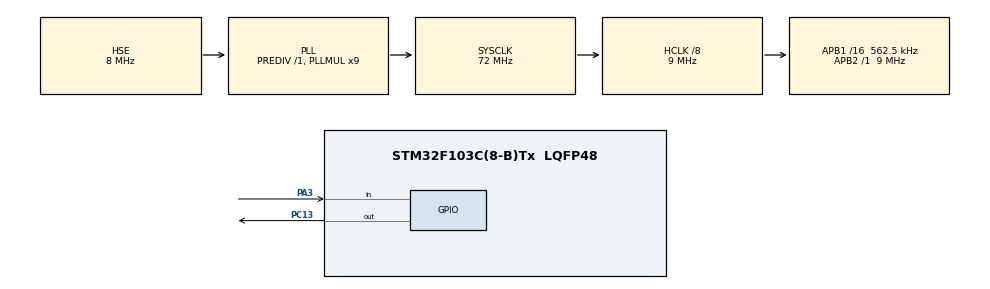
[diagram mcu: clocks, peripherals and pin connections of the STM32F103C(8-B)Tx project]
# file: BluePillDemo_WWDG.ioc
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Mcu.Family=STM32F1
Mcu.Name=STM32F103C(8-B)Tx
Mcu.Package=LQFP48
NVIC.PriorityGroup=NVIC_PRIORITYGROUP_4
PA13.Mode=Serial_Wire
PA13.Signal=SYS_JTMS-SWDIO
PA14.Mode=Serial_Wire
PA14.Signal=SYS_JTCK-SWCLK
PA3.GPIO_PuPd=GPIO_PULLUP
PA3.Signal=GPIO_Input
PC13-TAMPER-RTC.Signal=GPIO_Output
PC14-OSC32_IN.Mode=LSE-External-Oscillator
PC14-OSC32_IN.Signal=RCC_OSC32_IN
PC15-OSC32_OUT.Mode=LSE-External-Oscillator
PC15-OSC32_OUT.Signal=RCC_OSC32_OUT
PD0-OSC_IN.Mode=HSE-External-Oscillator
PD0-OSC_IN.Signal=RCC_OSC_IN
PD1-OSC_OUT.Mode=HSE-External-Oscillator
PD1-OSC_OUT.Signal=RCC_OSC_OUT
ProjectManager.HeapSize=0x200
ProjectManager.StackSize=0x400
ProjectManager.TargetToolchain=STM32CubeIDE
RCC.AHBCLKDivider=RCC_SYSCLK_DIV8
RCC.AHBFreq_Value=9000000
RCC.APB1CLKDivider=RCC_HCLK_DIV16
RCC.APB1Freq_Value=562500
RCC.APB1TimFreq_Value=1125000
RCC.APB2Freq_Value=9000000
RCC.APB2TimFreq_Value=9000000
RCC.HCLKFreq_Value=9000000
RCC.PLLMUL=RCC_PLL_MUL9
RCC.PLLSourceVirtual=RCC_PLLSOURCE_HSE
RCC.SYSCLKFreq_VALUE=72000000
RCC.SYSCLKSource=RCC_SYSCLKSOURCE_PLLCLK
RCC.USBFreq_Value=72000000
VP_WWDG_VS_WWDG.Mode=WWDG_Activate
WWDG.Counter=0x7f
WWDG.Prescaler=WWDG_PRESCALER_8
WWDG.Window=0x5f
board=custom

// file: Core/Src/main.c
/* USER CODE BEGIN Header */
/**
  ******************************************************************************
  * @file           : main.c
  * @brief          : Main program body
  ******************************************************************************
  * @attention
  *
  * <h2><center>&copy; Copyright (c) 2020 STMicroelectronics.
  * All rights reserved.</center></h2>
  *
  * This software component is licensed by ST under BSD 3-Clause license,
  * the "License"; You may not use this file except in compliance with the
  * License. You may obtain a copy of the License at:
  *                        opensource.org/licenses/BSD-3-Clause
  *
  ******************************************************************************
  */
/* USER CODE END Header */

#include "main.h"

WWDG_HandleTypeDef hwwdg;

void SystemClock_Config(void);
static void MX_GPIO_Init(void);
static void MX_WWDG_Init(void);

int main(void)
{

  /* MCU Configuration--------------------------------------------------------*/

  /* Reset of all peripherals, Initializes the Flash interface and the Systick. */
  HAL_Init();

  /* Configure the system clock */
  SystemClock_Config();

  /* Initialize all configured peripherals */
  MX_GPIO_Init();
  MX_WWDG_Init();
  /* USER CODE BEGIN 2 */

  // check the reset reason and if it's Window Watchdog flash led
  if (__HAL_RCC_GET_FLAG(RCC_FLAG_WWDGRST))
  {
    while (1)
	{
	  HAL_GPIO_WritePin(GPIOC, GPIO_PIN_13, GPIO_PIN_RESET);
	  HAL_Delay(50U);
	  HAL_GPIO_WritePin(GPIOC, GPIO_PIN_13, GPIO_PIN_SET);
	  HAL_Delay(50U);
	}
  }

  /* USER CODE END 2 */

  /* Infinite loop */
  while (1)
  {

    /* USER CODE BEGIN 3 */

	// check for start of window period
    if ((READ_REG(hwwdg.Instance->CR) & 0x7f) < 0x5f)
    {
      // in window period, led on
	  HAL_GPIO_WritePin(GPIOC, GPIO_PIN_13, GPIO_PIN_RESET);
    }
    else
    {
      // not in window period, led off
	  HAL_GPIO_WritePin(GPIOC, GPIO_PIN_13, GPIO_PIN_SET);
    }

    // check for a button press and if pressed refresh watchdog
    if (HAL_GPIO_ReadPin(GPIOA, GPIO_PIN_3) == GPIO_PIN_RESET)
    {
	  HAL_WWDG_Refresh(&hwwdg);

	  // prevent button bounce which would refresh the watchdog again outside of its period and cause a reset
	  HAL_Delay(200U);
    }
  }
  /* USER CODE END 3 */
}

void SystemClock_Config(void)
{
  RCC_OscInitTypeDef RCC_OscInitStruct = {0};
  RCC_ClkInitTypeDef RCC_ClkInitStruct = {0};

  /** Initializes the CPU, AHB and APB busses clocks
  */
  RCC_OscInitStruct.OscillatorType = RCC_OSCILLATORTYPE_HSE;
  RCC_OscInitStruct.HSEState = RCC_HSE_ON;
  RCC_OscInitStruct.HSEPredivValue = RCC_HSE_PREDIV_DIV1;
  RCC_OscInitStruct.HSIState = RCC_HSI_ON;
  RCC_OscInitStruct.PLL.PLLState = RCC_PLL_ON;
  RCC_OscInitStruct.PLL.PLLSource = RCC_PLLSOURCE_HSE;
  RCC_OscInitStruct.PLL.PLLMUL = RCC_PLL_MUL9;
  if (HAL_RCC_OscConfig(&RCC_OscInitStruct) != HAL_OK)
  {
    Error_Handler();
  }
  /** Initializes the CPU, AHB and APB busses clocks
  */
  RCC_ClkInitStruct.ClockType = RCC_CLOCKTYPE_HCLK|RCC_CLOCKTYPE_SYSCLK
                              |RCC_CLOCKTYPE_PCLK1|RCC_CLOCKTYPE_PCLK2;
  RCC_ClkInitStruct.SYSCLKSource = RCC_SYSCLKSOURCE_PLLCLK;
  RCC_ClkInitStruct.AHBCLKDivider = RCC_SYSCLK_DIV8;
  RCC_ClkInitStruct.APB1CLKDivider = RCC_HCLK_DIV16;
  RCC_ClkInitStruct.APB2CLKDivider = RCC_HCLK_DIV1;

  if (HAL_RCC_ClockConfig(&RCC_ClkInitStruct, FLASH_LATENCY_2) != HAL_OK)
  {
    Error_Handler();
  }
}

static void MX_WWDG_Init(void)
{

  hwwdg.Instance = WWDG;
  hwwdg.Init.Prescaler = WWDG_PRESCALER_8;
  hwwdg.Init.Window = 0x5f;
  hwwdg.Init.Counter = 0x7f;
  hwwdg.Init.EWIMode = WWDG_EWI_DISABLE;
  if (HAL_WWDG_Init(&hwwdg) != HAL_OK)
  {
    Error_Handler();
  }

}

static void MX_GPIO_Init(void)
{
  GPIO_InitTypeDef GPIO_InitStruct = {0};

  /* GPIO Ports Clock Enable */
  __HAL_RCC_GPIOC_CLK_ENABLE();
  __HAL_RCC_GPIOD_CLK_ENABLE();
  __HAL_RCC_GPIOA_CLK_ENABLE();

  /*Configure GPIO pin Output Level */
  HAL_GPIO_WritePin(GPIOC, GPIO_PIN_13, GPIO_PIN_RESET);

  /*Configure GPIO pin : PC13 */
  GPIO_InitStruct.Pin = GPIO_PIN_13;
  GPIO_InitStruct.Mode = GPIO_MODE_OUTPUT_PP;
  GPIO_InitStruct.Pull = GPIO_NOPULL;
  GPIO_InitStruct.Speed = GPIO_SPEED_FREQ_LOW;
  HAL_GPIO_Init(GPIOC, &GPIO_InitStruct);

  /*Configure GPIO pin : PA3 */
  GPIO_InitStruct.Pin = GPIO_PIN_3;
  GPIO_InitStruct.Mode = GPIO_MODE_INPUT;
  GPIO_InitStruct.Pull = GPIO_PULLUP;
  HAL_GPIO_Init(GPIOA, &GPIO_InitStruct);

}

void Error_Handler(void)
{
}

/************************ (C) COPYRIGHT STMicroelectronics *****END OF FILE****/
